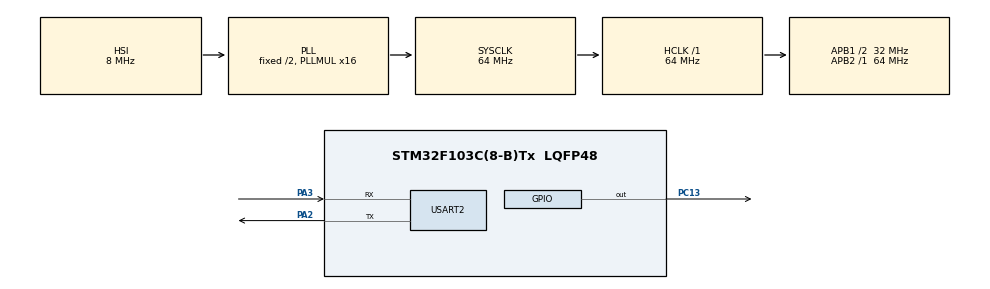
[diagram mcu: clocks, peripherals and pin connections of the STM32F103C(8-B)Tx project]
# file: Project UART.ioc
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Dma.Request0=USART2_TX
Dma.USART2_TX.0.Direction=DMA_MEMORY_TO_PERIPH
Dma.USART2_TX.0.Instance=DMA1_Channel7
Dma.USART2_TX.0.MemDataAlignment=DMA_MDATAALIGN_BYTE
Dma.USART2_TX.0.MemInc=DMA_MINC_ENABLE
Dma.USART2_TX.0.Mode=DMA_CIRCULAR
Dma.USART2_TX.0.PeriphDataAlignment=DMA_PDATAALIGN_BYTE
Dma.USART2_TX.0.PeriphInc=DMA_PINC_DISABLE
Dma.USART2_TX.0.Priority=DMA_PRIORITY_LOW
Mcu.Family=STM32F1
Mcu.Name=STM32F103C(8-B)Tx
Mcu.Package=LQFP48
NVIC.DMA1_Channel7_IRQn=true\:0\:0\:false\:false\:true\:false\:true\:true
NVIC.PriorityGroup=NVIC_PRIORITYGROUP_4
NVIC.TIM2_IRQn=true\:3\:0\:true\:false\:true\:true\:true\:true
NVIC.TIM3_IRQn=true\:4\:0\:true\:false\:true\:true\:true\:true
NVIC.USART2_IRQn=true\:1\:0\:true\:false\:true\:true\:true\:true
PA2.Mode=Asynchronous
PA2.Signal=USART2_TX
PA3.Mode=Asynchronous
PA3.Signal=USART2_RX
PC13-TAMPER-RTC.Signal=GPIO_Output
ProjectManager.HeapSize=0x200
ProjectManager.StackSize=0x400
ProjectManager.TargetToolchain=MDK-ARM V5.32
RCC.AHBFreq_Value=64000000
RCC.APB1CLKDivider=RCC_HCLK_DIV2
RCC.APB1Freq_Value=32000000
RCC.APB1TimFreq_Value=64000000
RCC.APB2Freq_Value=64000000
RCC.APB2TimFreq_Value=64000000
RCC.HCLKFreq_Value=64000000
RCC.PLLMUL=RCC_PLL_MUL16
RCC.SYSCLKFreq_VALUE=64000000
RCC.SYSCLKSource=RCC_SYSCLKSOURCE_PLLCLK
RCC.USBFreq_Value=64000000
TIM2.Period=999
TIM2.Prescaler=63999
TIM3.Period=100
TIM3.Prescaler=63999
USART2.VirtualMode=VM_ASYNC
VP_SYS_VS_ND.Mode=No_Debug
VP_TIM2_VS_ClockSourceINT.Mode=Internal
VP_TIM3_VS_ClockSourceINT.Mode=Internal
board=custom

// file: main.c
/* USER CODE BEGIN Header */
/**
  ******************************************************************************
  * @file           : main.c
  * @brief          : Main program body
  ******************************************************************************
  * @attention
  *
  * Copyright (c) 2023 STMicroelectronics.
  * All rights reserved.
  *
  * This software is licensed under terms that can be found in the LICENSE file
  * in the root directory of this software component.
  * If no LICENSE file comes with this software, it is provided AS-IS.
  *
  ******************************************************************************
  */
/* USER CODE END Header */
#include "main.h"
#include "string.h"

TIM_HandleTypeDef htim2;
TIM_HandleTypeDef htim3;

UART_HandleTypeDef huart2;
DMA_HandleTypeDef hdma_usart2_tx;

void SystemClock_Config(void);
static void MX_GPIO_Init(void);
static void MX_DMA_Init(void);
static void MX_TIM2_Init(void);
static void MX_USART2_UART_Init(void);
static void MX_TIM3_Init(void);

void Delay(int t){
while(t){
TIM3->CNT = 0U;
	while((TIM3->CNT ) < 1000){}
t--;

}

}

/* USER CODE BEGIN 0 */
char buffer[50];
uint8_t get_data;
int count;
char *start_sentence = "getting value from lora ... \n";
char *time = " data o tren nhan vao luc x hour y min z second \n  DATA : ";

void HAL_UART_RxCpltCallback(UART_HandleTypeDef *huart)
{
  if(huart->Instance == USART2){
	while(get_data != '@'){
		buffer[count++] = get_data;
		HAL_UART_Receive(&huart2,&get_data, 1, HAL_MAX_DELAY);
	}
	HAL_TIM_Base_Start_IT(&htim2);
	HAL_TIM_Base_Start_IT(&htim3);
	}
}

void HAL_TIM_PeriodElapsedCallback(TIM_HandleTypeDef *htim)
{
if(htim->Instance == TIM2){
if(get_data == '@'){
count = 0;
		HAL_UART_Transmit(&huart2, (uint8_t *) time, strlen(time), HAL_MAX_DELAY);
	HAL_UART_Transmit_IT(&huart2, (uint8_t *) buffer, strlen(buffer));
	int i = 0;
	for(i = 0 ; i  < 50; i++){
		HAL_GPIO_TogglePin(GPIOC, GPIO_PIN_13);
    Delay(90);
	}
	HAL_GPIO_WritePin(GPIOC, GPIO_PIN_13, GPIO_PIN_SET);

}
HAL_TIM_Base_Stop_IT(&htim2);

}

}

/* USER CODE END 0 */

int main(void)
{

  /* MCU Configuration--------------------------------------------------------*/

  /* Reset of all peripherals, Initializes the Flash interface and the Systick. */
  HAL_Init();

  /* Configure the system clock */
  SystemClock_Config();

  /* Initialize all configured peripherals */
  MX_GPIO_Init();
  MX_DMA_Init();
  MX_TIM2_Init();
  MX_USART2_UART_Init();
  MX_TIM3_Init();
	HAL_TIM_Base_Start(&htim3);
  /* USER CODE BEGIN 2 */
HAL_UART_Transmit(&huart2,(uint8_t*) start_sentence, strlen(start_sentence), 100);
HAL_GPIO_WritePin(GPIOC, GPIO_PIN_13, GPIO_PIN_SET);
  /* USER CODE END 2 */

  /* Infinite loop */
  while (1)
  {
HAL_UART_Receive_IT(&huart2, &get_data, 1);
  }
}

void SystemClock_Config(void)
{
  RCC_OscInitTypeDef RCC_OscInitStruct = {0};
  RCC_ClkInitTypeDef RCC_ClkInitStruct = {0};

  /** Initializes the RCC Oscillators according to the specified parameters
  * in the RCC_OscInitTypeDef structure.
  */
  RCC_OscInitStruct.OscillatorType = RCC_OSCILLATORTYPE_HSI;
  RCC_OscInitStruct.HSIState = RCC_HSI_ON;
  RCC_OscInitStruct.HSICalibrationValue = RCC_HSICALIBRATION_DEFAULT;
  RCC_OscInitStruct.PLL.PLLState = RCC_PLL_ON;
  RCC_OscInitStruct.PLL.PLLSource = RCC_PLLSOURCE_HSI_DIV2;
  RCC_OscInitStruct.PLL.PLLMUL = RCC_PLL_MUL16;
  if (HAL_RCC_OscConfig(&RCC_OscInitStruct) != HAL_OK)
  {
    Error_Handler();
  }

  /** Initializes the CPU, AHB and APB buses clocks
  */
  RCC_ClkInitStruct.ClockType = RCC_CLOCKTYPE_HCLK|RCC_CLOCKTYPE_SYSCLK
                              |RCC_CLOCKTYPE_PCLK1|RCC_CLOCKTYPE_PCLK2;
  RCC_ClkInitStruct.SYSCLKSource = RCC_SYSCLKSOURCE_PLLCLK;
  RCC_ClkInitStruct.AHBCLKDivider = RCC_SYSCLK_DIV1;
  RCC_ClkInitStruct.APB1CLKDivider = RCC_HCLK_DIV2;
  RCC_ClkInitStruct.APB2CLKDivider = RCC_HCLK_DIV1;

  if (HAL_RCC_ClockConfig(&RCC_ClkInitStruct, FLASH_LATENCY_2) != HAL_OK)
  {
    Error_Handler();
  }
}

static void MX_TIM2_Init(void)
{

  TIM_ClockConfigTypeDef sClockSourceConfig = {0};
  TIM_MasterConfigTypeDef sMasterConfig = {0};

  htim2.Instance = TIM2;
  htim2.Init.Prescaler = 63999;
  htim2.Init.CounterMode = TIM_COUNTERMODE_UP;
  htim2.Init.Period = 999;
  htim2.Init.ClockDivision = TIM_CLOCKDIVISION_DIV1;
  htim2.Init.AutoReloadPreload = TIM_AUTORELOAD_PRELOAD_DISABLE;
  if (HAL_TIM_Base_Init(&htim2) != HAL_OK)
  {
    Error_Handler();
  }
  sClockSourceConfig.ClockSource = TIM_CLOCKSOURCE_INTERNAL;
  if (HAL_TIM_ConfigClockSource(&htim2, &sClockSourceConfig) != HAL_OK)
  {
    Error_Handler();
  }
  sMasterConfig.MasterOutputTrigger = TIM_TRGO_RESET;
  sMasterConfig.MasterSlaveMode = TIM_MASTERSLAVEMODE_DISABLE;
  if (HAL_TIMEx_MasterConfigSynchronization(&htim2, &sMasterConfig) != HAL_OK)
  {
    Error_Handler();
  }

}

static void MX_TIM3_Init(void)
{

  TIM_ClockConfigTypeDef sClockSourceConfig = {0};
  TIM_MasterConfigTypeDef sMasterConfig = {0};

  htim3.Instance = TIM3;
  htim3.Init.Prescaler = 63;
  htim3.Init.CounterMode = TIM_COUNTERMODE_UP;
  htim3.Init.Period = 9999;
  htim3.Init.ClockDivision = TIM_CLOCKDIVISION_DIV1;
  htim3.Init.AutoReloadPreload = TIM_AUTORELOAD_PRELOAD_DISABLE;
  if (HAL_TIM_Base_Init(&htim3) != HAL_OK)
  {
    Error_Handler();
  }
  sClockSourceConfig.ClockSource = TIM_CLOCKSOURCE_INTERNAL;
  if (HAL_TIM_ConfigClockSource(&htim3, &sClockSourceConfig) != HAL_OK)
  {
    Error_Handler();
  }
  sMasterConfig.MasterOutputTrigger = TIM_TRGO_RESET;
  sMasterConfig.MasterSlaveMode = TIM_MASTERSLAVEMODE_DISABLE;
  if (HAL_TIMEx_MasterConfigSynchronization(&htim3, &sMasterConfig) != HAL_OK)
  {
    Error_Handler();
  }

}

static void MX_USART2_UART_Init(void)
{

  huart2.Instance = USART2;
  huart2.Init.BaudRate = 115200;
  huart2.Init.WordLength = UART_WORDLENGTH_8B;
  huart2.Init.StopBits = UART_STOPBITS_1;
  huart2.Init.Parity = UART_PARITY_NONE;
  huart2.Init.Mode = UART_MODE_TX_RX;
  huart2.Init.HwFlowCtl = UART_HWCONTROL_NONE;
  huart2.Init.OverSampling = UART_OVERSAMPLING_16;
  if (HAL_UART_Init(&huart2) != HAL_OK)
  {
    Error_Handler();
  }

}

static void MX_DMA_Init(void)
{

  /* DMA controller clock enable */
  __HAL_RCC_DMA1_CLK_ENABLE();

  /* DMA interrupt init */
  /* DMA1_Channel7_IRQn interrupt configuration */
  HAL_NVIC_SetPriority(DMA1_Channel7_IRQn, 0, 0);
  HAL_NVIC_EnableIRQ(DMA1_Channel7_IRQn);

}

static void MX_GPIO_Init(void)
{
  GPIO_InitTypeDef GPIO_InitStruct = {0};

  /* GPIO Ports Clock Enable */
  __HAL_RCC_GPIOC_CLK_ENABLE();
  __HAL_RCC_GPIOA_CLK_ENABLE();

  /*Configure GPIO pin Output Level */
  HAL_GPIO_WritePin(GPIOC, GPIO_PIN_13, GPIO_PIN_RESET);

  /*Configure GPIO pin : PC13 */
  GPIO_InitStruct.Pin = GPIO_PIN_13;
  GPIO_InitStruct.Mode = GPIO_MODE_OUTPUT_PP;
  GPIO_InitStruct.Pull = GPIO_NOPULL;
  GPIO_InitStruct.Speed = GPIO_SPEED_FREQ_LOW;
  HAL_GPIO_Init(GPIOC, &GPIO_InitStruct);

}

void Error_Handler(void)
{
  __disable_irq();
  while (1)
  {
  }
}
